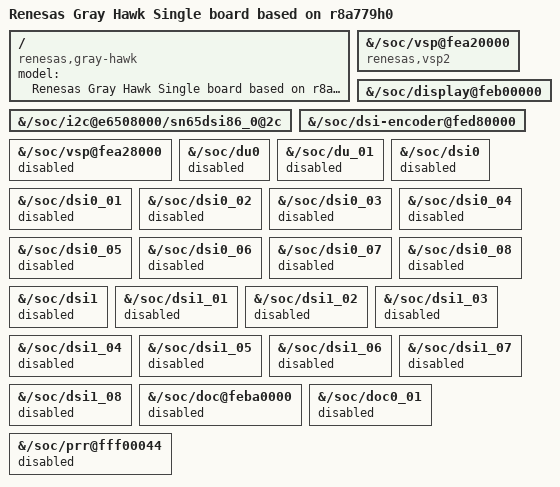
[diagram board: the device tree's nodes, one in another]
// SPDX-License-Identifier: (GPL-2.0-only OR BSD-2-Clause)
/*
 * Device Tree Source for UIO on the Gray Hawk CPU and BreakOut boards
 *
 * Copyright (C) 2023 Renesas Electronics Corp.
 */

/dts-v1/;
#include "r8a779h0-uio.dtsi"
#include "r8a779h0-gray-hawk-uio-common.dtsi"

/ {
	model = "Renesas Gray Hawk Single board based on r8a779h0";
	compatible = "renesas,gray-hawk", "renesas,r8a779h0-uio",
		     "renesas,r8a779h0";
};

&{/soc/i2c@e6508000/sn65dsi86_0@2c} {
	status = "okay";
};

&{/soc/vsp@fea20000} {
	compatible = "renesas,vsp2";
};

&{/soc/display@feb00000} {
	status = "okay";
};

&{/soc/dsi-encoder@fed80000} {
	status = "okay";
};

&{/soc/vsp@fea28000} {
	status = "disabled";
};

&{/soc/du0} {
	status = "disabled";
};

&{/soc/du_01} {
	status = "disabled";
};

&{/soc/dsi0} {
	status = "disabled";
};

&{/soc/dsi0_01} {
	status = "disabled";
};

&{/soc/dsi0_02} {
	status = "disabled";
};

&{/soc/dsi0_03} {
	status = "disabled";
};

&{/soc/dsi0_04} {
	status = "disabled";
};

&{/soc/dsi0_05} {
	status = "disabled";
};

&{/soc/dsi0_06} {
	status = "disabled";
};

&{/soc/dsi0_07} {
	status = "disabled";
};

&{/soc/dsi0_08} {
	status = "disabled";
};

&{/soc/dsi1} {
	status = "disabled";
};

&{/soc/dsi1_01} {
	status = "disabled";
};

&{/soc/dsi1_02} {
	status = "disabled";
};

&{/soc/dsi1_03} {
	status = "disabled";
};

&{/soc/dsi1_04} {
	status = "disabled";
};

&{/soc/dsi1_05} {
	status = "disabled";
};

&{/soc/dsi1_06} {
	status = "disabled";
};

&{/soc/dsi1_07} {
	status = "disabled";
};

&{/soc/dsi1_08} {
	status = "disabled";
};

&{/soc/doc@feba0000} {
	status = "disabled";
};

&{/soc/doc0_01} {
	status = "disabled";
};

&{/soc/prr@fff00044} {
	status = "disabled";
};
